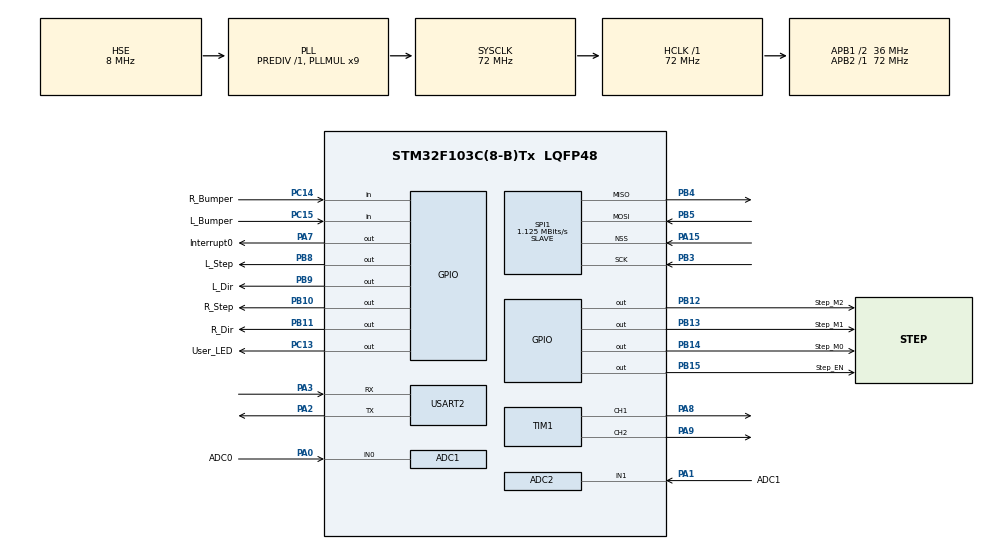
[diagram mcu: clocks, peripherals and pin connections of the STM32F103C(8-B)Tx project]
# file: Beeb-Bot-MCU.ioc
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ADC1.Channel-0\#ChannelRegularConversion=ADC_CHANNEL_0
ADC1.NbrOfConversionFlag=1
ADC1.Rank-0\#ChannelRegularConversion=1
ADC1.SamplingTime-0\#ChannelRegularConversion=ADC_SAMPLETIME_1CYCLE_5
ADC1.master=1
ADC2.Channel-0\#ChannelRegularConversion=ADC_CHANNEL_1
ADC2.NbrOfConversionFlag=1
ADC2.Rank-0\#ChannelRegularConversion=1
ADC2.SamplingTime-0\#ChannelRegularConversion=ADC_SAMPLETIME_1CYCLE_5
Mcu.Family=STM32F1
Mcu.Name=STM32F103C(8-B)Tx
Mcu.Package=LQFP48
NVIC.PriorityGroup=NVIC_PRIORITYGROUP_4
NVIC.SPI1_IRQn=true\:1\:0\:true\:false\:true\:true\:true
NVIC.TIM2_IRQn=true\:5\:0\:true\:false\:true\:true\:true
NVIC.TIM3_IRQn=true\:5\:0\:true\:false\:true\:true\:true
NVIC.TIM4_IRQn=true\:5\:0\:true\:false\:true\:true\:true
PA0-WKUP.GPIO_Label=ADC0
PA0-WKUP.Signal=ADCx_IN0
PA1.GPIO_Label=ADC1
PA1.Signal=ADCx_IN1
PA13.Signal=SYS_JTMS-SWDIO
PA14.Signal=SYS_JTCK-SWCLK
PA15.GPIO_PuPd=GPIO_PULLUP
PA15.Mode=NSS_Signal_Hard_Input
PA15.Signal=SPI1_NSS
PA2.Mode=Asynchronous
PA2.Signal=USART2_TX
PA3.Mode=Asynchronous
PA3.Signal=USART2_RX
PA7.GPIO_Label=Interrupt0
PA7.Signal=GPIO_Output
PA8.Signal=S_TIM1_CH1
PA9.Signal=S_TIM1_CH2
PB10.GPIO_Label=R_Step
PB10.GPIO_Speed=GPIO_SPEED_FREQ_HIGH
PB10.Signal=GPIO_Output
PB11.GPIO_Label=R_Dir
PB11.Signal=GPIO_Output
PB12.GPIO_Label=Step_M2
PB12.Signal=GPIO_Output
PB13.GPIO_Label=Step_M1
PB13.Signal=GPIO_Output
PB14.GPIO_Label=Step_M0
PB14.Signal=GPIO_Output
PB15.GPIO_Label=Step_EN
PB15.Signal=GPIO_Output
PB3.Mode=Full_Duplex_Slave
PB3.Signal=SPI1_SCK
PB4.Mode=Full_Duplex_Slave
PB4.Signal=SPI1_MISO
PB5.Mode=Full_Duplex_Slave
PB5.Signal=SPI1_MOSI
PB8.GPIO_Label=L_Step
PB8.GPIO_Speed=GPIO_SPEED_FREQ_HIGH
PB8.Signal=GPIO_Output
PB9.GPIO_Label=L_Dir
PB9.Signal=GPIO_Output
PC13-TAMPER-RTC.GPIO_Label=User_LED
PC13-TAMPER-RTC.Signal=GPIO_Output
PC14-OSC32_IN.GPIO_Label=R_Bumper
PC14-OSC32_IN.GPIO_PuPd=GPIO_PULLDOWN
PC14-OSC32_IN.Signal=GPIO_Input
PC15-OSC32_OUT.GPIO_Label=L_Bumper
PC15-OSC32_OUT.GPIO_PuPd=GPIO_PULLDOWN
PC15-OSC32_OUT.Signal=GPIO_Input
PD0-OSC_IN.Mode=HSE-External-Oscillator
PD0-OSC_IN.Signal=RCC_OSC_IN
PD1-OSC_OUT.Mode=HSE-External-Oscillator
PD1-OSC_OUT.Signal=RCC_OSC_OUT
ProjectManager.HeapSize=0x200
ProjectManager.StackSize=0x400
ProjectManager.TargetToolchain=Other Toolchains (GPDSC)
RCC.ADCPresc=RCC_ADCPCLK2_DIV6
RCC.AHBFreq_Value=72000000
RCC.APB1CLKDivider=RCC_HCLK_DIV2
RCC.APB1Freq_Value=36000000
RCC.APB1TimFreq_Value=72000000
RCC.APB2Freq_Value=72000000
RCC.APB2TimFreq_Value=72000000
RCC.HCLKFreq_Value=72000000
RCC.PLLMUL=RCC_PLL_MUL9
RCC.PLLSourceVirtual=RCC_PLLSOURCE_HSE
RCC.SYSCLKFreq_VALUE=72000000
RCC.SYSCLKSource=RCC_SYSCLKSOURCE_PLLCLK
RCC.USBFreq_Value=48000000
RCC.USBPrescaler=RCC_USBCLKSOURCE_PLL_DIV1_5
SH.ADCx_IN0.0=ADC1_IN0,IN0
SH.ADCx_IN1.0=ADC2_IN1,IN1
SH.S_TIM1_CH1.0=TIM1_CH1,Output Compare1 CH1
SH.S_TIM1_CH2.0=TIM1_CH2,Output Compare2 CH2
SPI1.BaudRatePrescaler=SPI_BAUDRATEPRESCALER_64
SPI1.CalculateBaudRate=1.125 MBits/s
SPI1.Direction=SPI_DIRECTION_2LINES
SPI1.Mode=SPI_MODE_SLAVE
SPI1.VirtualNSS=VM_NSSHARD
SPI1.VirtualType=VM_SLAVE
TIM1.Channel-Output\ Compare1\ CH1=TIM_CHANNEL_1
TIM1.Channel-Output\ Compare2\ CH2=TIM_CHANNEL_2
TIM2.Channel-Output\ Compare1\ No\ Output=TIM_CHANNEL_1
TIM3.Channel-Output\ Compare1\ No\ Output=TIM_CHANNEL_1
TIM4.Channel-Output\ Compare1\ No\ Output=TIM_CHANNEL_1
USART2.VirtualMode=VM_ASYNC
VP_SYS_VS_ND.Mode=No_Debug
VP_TIM1_VS_ClockSourceINT.Mode=Internal
VP_TIM2_VS_ClockSourceINT.Mode=Internal
VP_TIM2_VS_no_output1.Mode=Output Compare1 No Output
VP_TIM3_VS_ClockSourceINT.Mode=Internal
VP_TIM3_VS_no_output1.Mode=Output Compare1 No Output
VP_TIM4_VS_ClockSourceINT.Mode=Internal
VP_TIM4_VS_no_output1.Mode=Output Compare1 No Output
board=custom

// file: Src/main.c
/* USER CODE BEGIN Header */
/**
  ******************************************************************************
  * @file           : main.c
  * @brief          : Main program body
  ******************************************************************************
  * @attention
  *
  * <h2><center>&copy; Copyright (c) 2020 STMicroelectronics.
  * All rights reserved.</center></h2>
  *
  * This software component is licensed by ST under BSD 3-Clause license,
  * the "License"; You may not use this file except in compliance with the
  * License. You may obtain a copy of the License at:
  *                        opensource.org/licenses/BSD-3-Clause
  *
  ******************************************************************************
  */
/* USER CODE END Header */

#include "main.h"
#include "adc.h"
#include "spi.h"
#include "tim.h"
#include "usart.h"
#include "gpio.h"

/* USER CODE BEGIN Includes */
#include "Beeb-Bot/beeb-bot-mcu.h"
/* USER CODE END Includes */

void SystemClock_Config(void);

int main(void)
{

  /* MCU Configuration--------------------------------------------------------*/

  /* Reset of all peripherals, Initializes the Flash interface and the Systick. */
  HAL_Init();

  /* USER CODE BEGIN Init */
  initialise();
  /* USER CODE END Init */

  /* Configure the system clock */
  SystemClock_Config();

  /* Initialize all configured peripherals */
  MX_GPIO_Init();
  MX_ADC1_Init();
  MX_ADC2_Init();
  MX_USART2_UART_Init();
  MX_TIM2_Init();
  MX_TIM3_Init();
  MX_SPI1_Init();
  MX_TIM1_Init();
  MX_TIM4_Init();

  /* Infinite loop */
  /* USER CODE BEGIN WHILE */
  while (1)
  {
    process();
    /* USER CODE END WHILE */

  }
}

void SystemClock_Config(void)
{
  RCC_OscInitTypeDef RCC_OscInitStruct = {0};
  RCC_ClkInitTypeDef RCC_ClkInitStruct = {0};
  RCC_PeriphCLKInitTypeDef PeriphClkInit = {0};

  /** Initializes the CPU, AHB and APB busses clocks
  */
  RCC_OscInitStruct.OscillatorType = RCC_OSCILLATORTYPE_HSE;
  RCC_OscInitStruct.HSEState = RCC_HSE_ON;
  RCC_OscInitStruct.HSEPredivValue = RCC_HSE_PREDIV_DIV1;
  RCC_OscInitStruct.HSIState = RCC_HSI_ON;
  RCC_OscInitStruct.PLL.PLLState = RCC_PLL_ON;
  RCC_OscInitStruct.PLL.PLLSource = RCC_PLLSOURCE_HSE;
  RCC_OscInitStruct.PLL.PLLMUL = RCC_PLL_MUL9;
  if (HAL_RCC_OscConfig(&RCC_OscInitStruct) != HAL_OK)
  {
    Error_Handler();
  }
  /** Initializes the CPU, AHB and APB busses clocks
  */
  RCC_ClkInitStruct.ClockType = RCC_CLOCKTYPE_HCLK|RCC_CLOCKTYPE_SYSCLK
                              |RCC_CLOCKTYPE_PCLK1|RCC_CLOCKTYPE_PCLK2;
  RCC_ClkInitStruct.SYSCLKSource = RCC_SYSCLKSOURCE_PLLCLK;
  RCC_ClkInitStruct.AHBCLKDivider = RCC_SYSCLK_DIV1;
  RCC_ClkInitStruct.APB1CLKDivider = RCC_HCLK_DIV2;
  RCC_ClkInitStruct.APB2CLKDivider = RCC_HCLK_DIV1;

  if (HAL_RCC_ClockConfig(&RCC_ClkInitStruct, FLASH_LATENCY_2) != HAL_OK)
  {
    Error_Handler();
  }
  PeriphClkInit.PeriphClockSelection = RCC_PERIPHCLK_ADC;
  PeriphClkInit.AdcClockSelection = RCC_ADCPCLK2_DIV6;
  if (HAL_RCCEx_PeriphCLKConfig(&PeriphClkInit) != HAL_OK)
  {
    Error_Handler();
  }
}

void Error_Handler(void)
{
}

/************************ (C) COPYRIGHT STMicroelectronics *****END OF FILE****/
